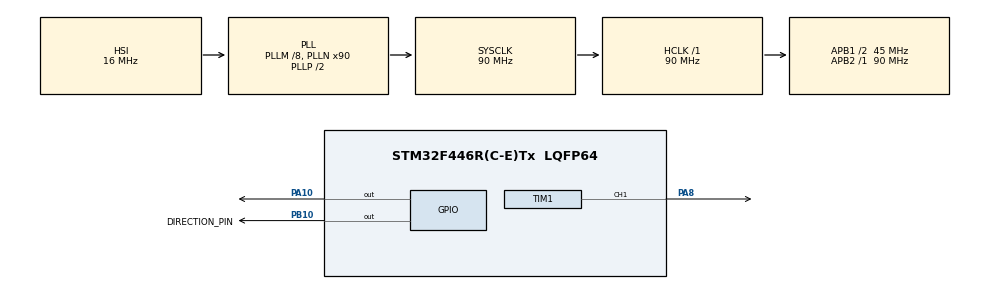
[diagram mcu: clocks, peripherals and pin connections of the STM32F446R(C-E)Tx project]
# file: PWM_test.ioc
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Dma.Request0=TIM1_CH1
Dma.TIM1_CH1.0.Direction=DMA_MEMORY_TO_PERIPH
Dma.TIM1_CH1.0.FIFOMode=DMA_FIFOMODE_DISABLE
Dma.TIM1_CH1.0.Instance=DMA2_Stream1
Dma.TIM1_CH1.0.MemDataAlignment=DMA_MDATAALIGN_HALFWORD
Dma.TIM1_CH1.0.MemInc=DMA_MINC_ENABLE
Dma.TIM1_CH1.0.Mode=DMA_NORMAL
Dma.TIM1_CH1.0.PeriphDataAlignment=DMA_PDATAALIGN_HALFWORD
Dma.TIM1_CH1.0.PeriphInc=DMA_PINC_DISABLE
Dma.TIM1_CH1.0.Priority=DMA_PRIORITY_LOW
Mcu.Family=STM32F4
Mcu.Name=STM32F446R(C-E)Tx
Mcu.Package=LQFP64
NVIC.DMA2_Stream1_IRQn=true\:0\:0\:false\:false\:true\:false\:true\:true
NVIC.PriorityGroup=NVIC_PRIORITYGROUP_4
PA10.Signal=GPIO_Output
PA13.Mode=Serial_Wire
PA13.Signal=SYS_JTMS-SWDIO
PA14.Mode=Serial_Wire
PA14.Signal=SYS_JTCK-SWCLK
PA8.Signal=S_TIM1_CH1
PB10.GPIO_Label=DIRECTION_PIN
PB10.GPIO_PuPd=GPIO_PULLDOWN
PB10.Signal=GPIO_Output
PH0-OSC_IN.Mode=HSE-External-Oscillator
PH0-OSC_IN.Signal=RCC_OSC_IN
PH1-OSC_OUT.Mode=HSE-External-Oscillator
PH1-OSC_OUT.Signal=RCC_OSC_OUT
ProjectManager.HeapSize=0x200
ProjectManager.StackSize=0x400
ProjectManager.TargetToolchain=STM32CubeIDE
RCC.AHBFreq_Value=90000000
RCC.APB1CLKDivider=RCC_HCLK_DIV2
RCC.APB1Freq_Value=45000000
RCC.APB1TimFreq_Value=90000000
RCC.APB2Freq_Value=90000000
RCC.APB2TimFreq_Value=90000000
RCC.CortexFreq_Value=90000000
RCC.HCLKFreq_Value=90000000
RCC.PLLM=8
RCC.PLLN=90
RCC.SYSCLKFreq_VALUE=90000000
RCC.SYSCLKSource=RCC_SYSCLKSOURCE_PLLCLK
RCC.USBFreq_Value=90000000
RCC.VCOOutputFreq_Value=180000000
SH.S_TIM1_CH1.0=TIM1_CH1,PWM Generation1 CH1
TIM1.Channel-PWM\ Generation1\ CH1=TIM_CHANNEL_1
TIM1.Period=100-1
TIM1.Prescaler=899
board=custom

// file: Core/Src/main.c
/* USER CODE BEGIN Header */
/**
  ******************************************************************************
  * @file           : main.c
  * @brief          : Main program body
  ******************************************************************************
  * @attention
  *
  * Copyright (c) 2024 STMicroelectronics.
  * All rights reserved.
  *
  * This software is licensed under terms that can be found in the LICENSE file
  * in the root directory of this software component.
  * If no LICENSE file comes with this software, it is provided AS-IS.
  *
  ******************************************************************************
  */
/* USER CODE END Header */
#include "main.h"

TIM_HandleTypeDef htim1;
DMA_HandleTypeDef hdma_tim1_ch1;

/* USER CODE BEGIN PV */
TIM_HandleTypeDef htim1;
/* USER CODE END PV */

void SystemClock_Config(void);
static void MX_GPIO_Init(void);
static void MX_DMA_Init(void);
static void MX_TIM1_Init(void);

int main(void)
{

  /* MCU Configuration--------------------------------------------------------*/

  /* Reset of all peripherals, Initializes the Flash interface and the Systick. */
  HAL_Init();

  /* Configure the system clock */
  SystemClock_Config();

  /* Initialize all configured peripherals */
  MX_GPIO_Init();
  MX_DMA_Init();
  MX_TIM1_Init();
  /* USER CODE BEGIN 2 */
  TIM_HandleTypeDef htim1;
  nidec_h24_start_pwm(&htim1, TIM_CHANNEL_1);

  /* USER CODE END 2 */

  /* Infinite loop */
  /* USER CODE BEGIN WHILE */

  while (1)
  {
	  HAL_Delay(1000);
	  TIM1->CCR1 = 50;
	  //nidec_h24_SetDutyCycle(&htim1, TIM_CHANNEL_1, 50);
	  //htim1.Instance->CCR1 = 50;
	  __HAL_TIM_SET_COMPARE(&htim1, TIM_CHANNEL_1, 50);
	  //HAL_Delay(3000);
	  TIM1->CCR1 = 75;
	  //nidec_h24_SetDutyCycle(&htim1, TIM_CHANNEL_1, 75);
	  //htim1.Instance->CCR1 = 75;
	  //__HAL_TIM_SET_COMPARE(&htim1, TIM_CHANNEL_1, 75);
	  HAL_Delay(3000);
	  //nidec_h24_SetDutyCycle(&htim1, TIM_CHANNEL_1, 100);
	  TIM1->CCR1 = 100;
	  //htim1.Instance->CCR1 = 100;
	  //__HAL_TIM_SET_COMPARE(&htim1, TIM_CHANNEL_1, 100);
	  HAL_Delay(3000);

	  HAL_GPIO_WritePin(GPIOB, DIRECTION_PIN_Pin, GPIO_PIN_SET);
	  HAL_Delay(3000);
	  TIM1->CCR1 = 50;
	  //nidec_h24_SetDutyCycle(&htim1, TIM_CHANNEL_1, 50);
	  //htim1.Instance->CCR1 = 50;
	  //__HAL_TIM_SET_COMPARE(&htim1, TIM_CHANNEL_1, 50);
	  HAL_Delay(3000);
	  TIM1->CCR1 = 75;
	  //nidec_h24_SetDutyCycle(&htim1, TIM_CHANNEL_1, 75);
	  //htim1.Instance->CCR1 = 75;
	  //__HAL_TIM_SET_COMPARE(&htim1, TIM_CHANNEL_1, 75);
	  HAL_Delay(3000);
	  //nidec_h24_SetDutyCycle(&htim1, TIM_CHANNEL_1, 100);
	  TIM1->CCR1 = 100;
	  //htim1.Instance->CCR1 = 100;
	  //__HAL_TIM_SET_COMPARE(&htim1, TIM_CHANNEL_1, 100);
	  HAL_Delay(3000);

	  HAL_GPIO_WritePin(GPIOB, DIRECTION_PIN_Pin, GPIO_PIN_RESET);

    /* USER CODE END WHILE */

  }
}

void SystemClock_Config(void)
{
  RCC_OscInitTypeDef RCC_OscInitStruct = {0};
  RCC_ClkInitTypeDef RCC_ClkInitStruct = {0};

  /** Configure the main internal regulator output voltage
  */
  __HAL_RCC_PWR_CLK_ENABLE();
  __HAL_PWR_VOLTAGESCALING_CONFIG(PWR_REGULATOR_VOLTAGE_SCALE3);

  /** Initializes the RCC Oscillators according to the specified parameters
  * in the RCC_OscInitTypeDef structure.
  */
  RCC_OscInitStruct.OscillatorType = RCC_OSCILLATORTYPE_HSI;
  RCC_OscInitStruct.HSIState = RCC_HSI_ON;
  RCC_OscInitStruct.HSICalibrationValue = RCC_HSICALIBRATION_DEFAULT;
  RCC_OscInitStruct.PLL.PLLState = RCC_PLL_ON;
  RCC_OscInitStruct.PLL.PLLSource = RCC_PLLSOURCE_HSI;
  RCC_OscInitStruct.PLL.PLLM = 8;
  RCC_OscInitStruct.PLL.PLLN = 90;
  RCC_OscInitStruct.PLL.PLLP = RCC_PLLP_DIV2;
  RCC_OscInitStruct.PLL.PLLQ = 2;
  RCC_OscInitStruct.PLL.PLLR = 2;
  if (HAL_RCC_OscConfig(&RCC_OscInitStruct) != HAL_OK)
  {
    Error_Handler();
  }

  /** Initializes the CPU, AHB and APB buses clocks
  */
  RCC_ClkInitStruct.ClockType = RCC_CLOCKTYPE_HCLK|RCC_CLOCKTYPE_SYSCLK
                              |RCC_CLOCKTYPE_PCLK1|RCC_CLOCKTYPE_PCLK2;
  RCC_ClkInitStruct.SYSCLKSource = RCC_SYSCLKSOURCE_PLLCLK;
  RCC_ClkInitStruct.AHBCLKDivider = RCC_SYSCLK_DIV1;
  RCC_ClkInitStruct.APB1CLKDivider = RCC_HCLK_DIV2;
  RCC_ClkInitStruct.APB2CLKDivider = RCC_HCLK_DIV1;

  if (HAL_RCC_ClockConfig(&RCC_ClkInitStruct, FLASH_LATENCY_2) != HAL_OK)
  {
    Error_Handler();
  }
}

static void MX_TIM1_Init(void)
{

  TIM_MasterConfigTypeDef sMasterConfig = {0};
  TIM_OC_InitTypeDef sConfigOC = {0};
  TIM_BreakDeadTimeConfigTypeDef sBreakDeadTimeConfig = {0};

  htim1.Instance = TIM1;
  htim1.Init.Prescaler = 899;
  htim1.Init.CounterMode = TIM_COUNTERMODE_UP;
  htim1.Init.Period = 100-1;
  htim1.Init.ClockDivision = TIM_CLOCKDIVISION_DIV1;
  htim1.Init.RepetitionCounter = 0;
  htim1.Init.AutoReloadPreload = TIM_AUTORELOAD_PRELOAD_DISABLE;
  if (HAL_TIM_PWM_Init(&htim1) != HAL_OK)
  {
    Error_Handler();
  }
  sMasterConfig.MasterOutputTrigger = TIM_TRGO_RESET;
  sMasterConfig.MasterSlaveMode = TIM_MASTERSLAVEMODE_DISABLE;
  if (HAL_TIMEx_MasterConfigSynchronization(&htim1, &sMasterConfig) != HAL_OK)
  {
    Error_Handler();
  }
  sConfigOC.OCMode = TIM_OCMODE_PWM1;
  sConfigOC.Pulse = 0;
  sConfigOC.OCPolarity = TIM_OCPOLARITY_HIGH;
  sConfigOC.OCNPolarity = TIM_OCNPOLARITY_HIGH;
  sConfigOC.OCFastMode = TIM_OCFAST_DISABLE;
  sConfigOC.OCIdleState = TIM_OCIDLESTATE_RESET;
  sConfigOC.OCNIdleState = TIM_OCNIDLESTATE_RESET;
  if (HAL_TIM_PWM_ConfigChannel(&htim1, &sConfigOC, TIM_CHANNEL_1) != HAL_OK)
  {
    Error_Handler();
  }
  sBreakDeadTimeConfig.OffStateRunMode = TIM_OSSR_DISABLE;
  sBreakDeadTimeConfig.OffStateIDLEMode = TIM_OSSI_DISABLE;
  sBreakDeadTimeConfig.LockLevel = TIM_LOCKLEVEL_OFF;
  sBreakDeadTimeConfig.DeadTime = 0;
  sBreakDeadTimeConfig.BreakState = TIM_BREAK_DISABLE;
  sBreakDeadTimeConfig.BreakPolarity = TIM_BREAKPOLARITY_HIGH;
  sBreakDeadTimeConfig.AutomaticOutput = TIM_AUTOMATICOUTPUT_DISABLE;
  if (HAL_TIMEx_ConfigBreakDeadTime(&htim1, &sBreakDeadTimeConfig) != HAL_OK)
  {
    Error_Handler();
  }
  HAL_TIM_MspPostInit(&htim1);

}

static void MX_DMA_Init(void)
{

  /* DMA controller clock enable */
  __HAL_RCC_DMA2_CLK_ENABLE();

  /* DMA interrupt init */
  /* DMA2_Stream1_IRQn interrupt configuration */
  HAL_NVIC_SetPriority(DMA2_Stream1_IRQn, 0, 0);
  HAL_NVIC_EnableIRQ(DMA2_Stream1_IRQn);

}

static void MX_GPIO_Init(void)
{
  GPIO_InitTypeDef GPIO_InitStruct = {0};

  /* GPIO Ports Clock Enable */
  __HAL_RCC_GPIOH_CLK_ENABLE();
  __HAL_RCC_GPIOB_CLK_ENABLE();
  __HAL_RCC_GPIOA_CLK_ENABLE();

  /*Configure GPIO pin Output Level */
  HAL_GPIO_WritePin(DIRECTION_PIN_GPIO_Port, DIRECTION_PIN_Pin, GPIO_PIN_RESET);

  /*Configure GPIO pin Output Level */
  HAL_GPIO_WritePin(GPIOA, GPIO_PIN_10, GPIO_PIN_RESET);

  /*Configure GPIO pin : DIRECTION_PIN_Pin */
  GPIO_InitStruct.Pin = DIRECTION_PIN_Pin;
  GPIO_InitStruct.Mode = GPIO_MODE_OUTPUT_PP;
  GPIO_InitStruct.Pull = GPIO_PULLDOWN;
  GPIO_InitStruct.Speed = GPIO_SPEED_FREQ_LOW;
  HAL_GPIO_Init(DIRECTION_PIN_GPIO_Port, &GPIO_InitStruct);

  /*Configure GPIO pin : PA10 */
  GPIO_InitStruct.Pin = GPIO_PIN_10;
  GPIO_InitStruct.Mode = GPIO_MODE_OUTPUT_PP;
  GPIO_InitStruct.Pull = GPIO_NOPULL;
  GPIO_InitStruct.Speed = GPIO_SPEED_FREQ_LOW;
  HAL_GPIO_Init(GPIOA, &GPIO_InitStruct);

}

void Error_Handler(void)
{
  __disable_irq();
  while (1)
  {
  }
}
